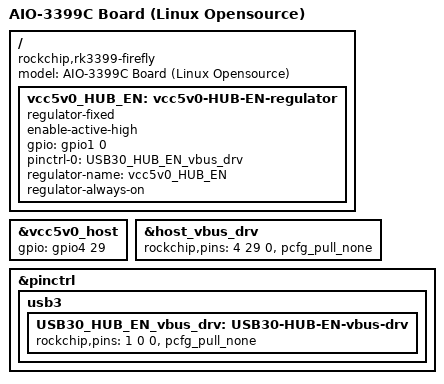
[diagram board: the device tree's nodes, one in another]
/*
 * Copyright (c) 2016 Fuzhou Rockchip Electronics Co., Ltd
 *
 * This file is dual-licensed: you can use it either under the terms
 * of the GPL or the X11 license, at your option. Note that this dual
 * licensing only applies to this file, and not this project as a
 * whole.
 *
 *  a) This file is free software; you can redistribute it and/or
 *     modify it under the terms of the GNU General Public License as
 *     published by the Free Software Foundation; either version 2 of the
 *     License, or (at your option) any later version.
 *
 *     This file is distributed in the hope that it will be useful,
 *     but WITHOUT ANY WARRANTY; without even the implied warranty of
 *     MERCHANTABILITY or FITNESS FOR A PARTICULAR PURPOSE.  See the
 *     GNU General Public License for more details.
 *
 * Or, alternatively,
 *     restriction, including without limitation the rights to use,
 *     copy, modify, merge, publish, distribute, sublicense, and/or
 *     sell copies of the Software, and to permit persons to whom the
 *     Software is furnished to do so, subject to the following
 *     conditions:
 *
 *     The above copyright notice and this permission notice shall be
 *     included in all copies or substantial portions of the Software.
 *
 *     THE SOFTWARE IS PROVIDED "AS IS", WITHOUT WARRANTY OF ANY KIND,
 *     EXPRESS OR IMPLIED, INCLUDING BUT NOT LIMITED TO THE WARRANTIES
 *     OF MERCHANTABILITY, FITNESS FOR A PARTICULAR PURPOSE AND
 *     NONINFRINGEMENT. IN NO EVENT SHALL THE AUTHORS OR COPYRIGHT
 *     HOLDERS BE LIABLE FOR ANY CLAIM, DAMAGES OR OTHER LIABILITY,
 *     WHETHER IN AN ACTION OF CONTRACT, TORT OR OTHERWISE, ARISING
 *     FROM, OUT OF OR IN CONNECTION WITH THE SOFTWARE OR THE USE OR
 *     OTHER DEALINGS IN THE SOFTWARE.
 */

/dts-v1/;

#include "rk3399-firefly-aioc.dtsi"

/ {
	model = "AIO-3399C Board (Linux Opensource)";
	compatible = "rockchip,rk3399-firefly", "rockchip,rk3399";

	vcc5v0_HUB_EN: vcc5v0-HUB-EN-regulator {
		compatible = "regulator-fixed";
		enable-active-high;
		gpio = <&gpio1 0 0>;
		pinctrl-names = "default";
		pinctrl-0 = <&USB30_HUB_EN_vbus_drv>;
		regulator-name = "vcc5v0_HUB_EN";
		regulator-always-on;
	};
};


&vcc5v0_host {
	gpio = <&gpio4 29 0>;
	/delete-property/ regulator-always-on;
};

&host_vbus_drv {
   rockchip,pins = <4 29 0 &pcfg_pull_none>;
};


&pinctrl {
	usb3 {
		USB30_HUB_EN_vbus_drv: USB30-HUB-EN-vbus-drv {
			rockchip,pins = <1 0 0 &pcfg_pull_none>;//pcfg_pull_none
		};
	};
};
